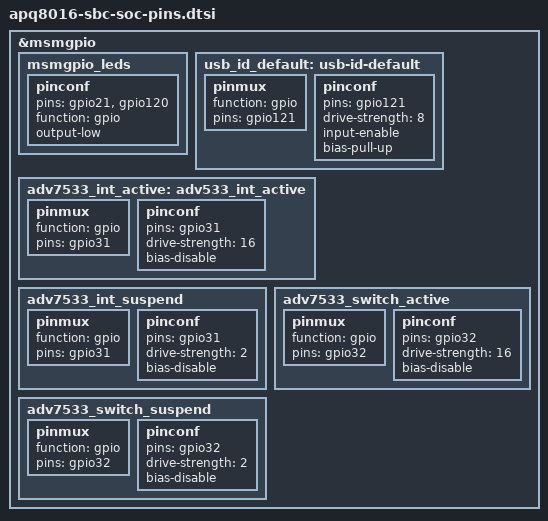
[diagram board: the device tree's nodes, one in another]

#include <dt-bindings/gpio/gpio.h>

&msmgpio {

	msmgpio_leds: msmgpio_leds {
		pinconf {
			pins = "gpio21", "gpio120";
			function = "gpio";
			output-low;
		};
	};

	usb_id_default: usb-id-default {
		pinmux {
			function = "gpio";
			pins = "gpio121";
		};

		pinconf {
			pins = "gpio121";
			drive-strength = <8>;
			input-enable;
			bias-pull-up;
		};
	};

	adv7533_int_active: adv533_int_active {
		pinmux {
			function = "gpio";
			pins = "gpio31";
		};
		pinconf {
			pins = "gpio31";
			drive-strength = <16>;
			bias-disable;
		};
	};

	adv7533_int_suspend: adv7533_int_suspend {
		pinmux {
			function = "gpio";
			pins = "gpio31";
		};
		pinconf {
			pins = "gpio31";
			drive-strength = <2>;
			bias-disable;
		};
	};

	adv7533_switch_active: adv7533_switch_active {
		pinmux {
			function = "gpio";
			pins = "gpio32";
		};
		pinconf {
			pins = "gpio32";
			drive-strength = <16>;
			bias-disable;
		};
	};

	adv7533_switch_suspend: adv7533_switch_suspend {
		pinmux {
			function = "gpio";
			pins = "gpio32";
		};
		pinconf {
			pins = "gpio32";
			drive-strength = <2>;
			bias-disable;
		};
	};
};
